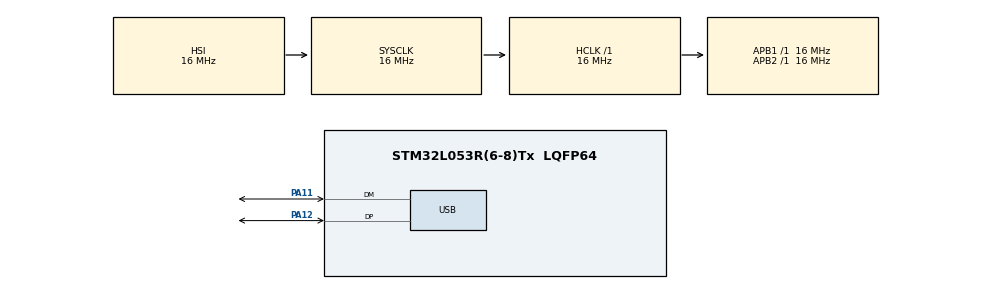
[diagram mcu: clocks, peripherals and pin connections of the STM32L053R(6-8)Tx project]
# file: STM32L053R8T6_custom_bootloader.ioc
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Mcu.Family=STM32L0
Mcu.Name=STM32L053R(6-8)Tx
Mcu.Package=LQFP64
NVIC.USB_IRQn=true\:0\:0\:false\:false\:true\:false\:true
PA11.Mode=Device
PA11.Signal=USB_DM
PA12.Mode=Device
PA12.Signal=USB_DP
PH0-OSC_IN.Mode=HSE-External-Clock-Source
PH0-OSC_IN.Signal=RCC_OSC_IN
ProjectManager.HeapSize=0x200
ProjectManager.StackSize=0x400
ProjectManager.TargetToolchain=STM32CubeIDE
RCC.AHBFreq_Value=16000000
RCC.APB1Freq_Value=16000000
RCC.APB1TimFreq_Value=16000000
RCC.APB2Freq_Value=16000000
RCC.APB2TimFreq_Value=16000000
RCC.HCLKFreq_Value=16000000
RCC.HSE_VALUE=8000000
RCC.HSI16_VALUE=16000000
RCC.HSI48MClockSelection=RCC_USBCLKSOURCE_HSI48
RCC.HSI48_VALUE=48000000
RCC.HSI_VALUE=16000000
RCC.LSE_VALUE=32768
RCC.MSI_VALUE=2097000
RCC.SYSCLKFreq_VALUE=16000000
RCC.SYSCLKSource=RCC_SYSCLKSOURCE_HSI
RCC.VCOOutputFreq_Value=48000000
USB_DEVICE.CLASS_NAME_FS=DFU
USB_DEVICE.USBD_DFU_APP_DEFAULT_ADD=0x08004000
USB_DEVICE.USBD_DFU_MEDIA=@Internal Flash   /0x08000000/128*128Ba,384*128Bg
USB_DEVICE.VirtualMode=Dfu
USB_DEVICE.VirtualModeFS=Dfu_FS
VP_USB_DEVICE_VS_USB_DEVICE_DFU_FS.Mode=DFU_FS
board=custom

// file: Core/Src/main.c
/* USER CODE BEGIN Header */
/**
  ******************************************************************************
  * @file           : main.c
  * @brief          : Main program body
  ******************************************************************************
  * @attention
  *
  * <h2><center>&copy; Copyright (c) 2021 STMicroelectronics.
  * All rights reserved.</center></h2>
  *
  * This software component is licensed by ST under Ultimate Liberty license
  * SLA0044, the "License"; You may not use this file except in compliance with
  * the License. You may obtain a copy of the License at:
  *                             www.st.com/SLA0044
  *
  ******************************************************************************
  */
/* USER CODE END Header */
#include "main.h"
#include "gpio.h"

/* USER CODE BEGIN Includes */
#include "usb_device.h"

#define EEPROM_ADDRESS 0x08080000
#define EEPROM_DFU_FLAG 100
/* USER CODE END Includes */

/* USER CODE BEGIN PV */
#if 0
HAL_StatusTypeDef eeprom_read_bit_32(uint16_t addr_idx, uint32_t *value);
HAL_StatusTypeDef eeprom_read_bit_32_type(uint32_t *value, uint16_t idx);
#endif
/* USER CODE END PV */

void SystemClock_Config(void);

int main(void)
{
  /* USER CODE BEGIN 1 */
  typedef void (*pFunction)(void);
  uint32_t JumpAddress;
  void (*Jump_To_Application)();
  /* USER CODE END 1 */

  /* MCU Configuration--------------------------------------------------------*/

  /* Reset of all peripherals, Initializes the Flash interface and the Systick. */
  HAL_Init();

  /* Configure the system clock */
  SystemClock_Config();

  /* Initialize all configured peripherals */
  MX_GPIO_Init();
  /* USER CODE BEGIN 2 */
  uint32_t main_get_dfu = *(uint32_t*)(EEPROM_ADDRESS + EEPROM_DFU_FLAG * 4);

#if 0
  eeprom_read_bit_32_type(&main_get_dfu,EEPROM_DFU_FLAG); // get dfu flag from eeprom idx 100
#endif

  if(main_get_dfu != 0x98765432)
  {
    JumpAddress = *(__IO uint32_t*) (USBD_DFU_APP_DEFAULT_ADD + 4);
    Jump_To_Application = (pFunction) JumpAddress;
    __set_MSP(*(__IO uint32_t*) USBD_DFU_APP_DEFAULT_ADD);
    Jump_To_Application();
  }

	MX_USB_DEVICE_Init();
  /* USER CODE END 2 */

  /* Infinite loop */
  while (1)
  {

  }
}

void SystemClock_Config(void)
{
  RCC_OscInitTypeDef RCC_OscInitStruct = {0};
  RCC_ClkInitTypeDef RCC_ClkInitStruct = {0};
  RCC_PeriphCLKInitTypeDef PeriphClkInit = {0};

  /** Configure the main internal regulator output voltage
  */
  __HAL_PWR_VOLTAGESCALING_CONFIG(PWR_REGULATOR_VOLTAGE_SCALE1);
  /** Initializes the RCC Oscillators according to the specified parameters
  * in the RCC_OscInitTypeDef structure.
  */
  RCC_OscInitStruct.OscillatorType = RCC_OSCILLATORTYPE_HSI|RCC_OSCILLATORTYPE_HSI48;
  RCC_OscInitStruct.HSIState = RCC_HSI_ON;
  RCC_OscInitStruct.HSICalibrationValue = RCC_HSICALIBRATION_DEFAULT;
  RCC_OscInitStruct.HSI48State = RCC_HSI48_ON;
  RCC_OscInitStruct.PLL.PLLState = RCC_PLL_NONE;
  if (HAL_RCC_OscConfig(&RCC_OscInitStruct) != HAL_OK)
  {
    Error_Handler();
  }
  /** Initializes the CPU, AHB and APB buses clocks
  */
  RCC_ClkInitStruct.ClockType = RCC_CLOCKTYPE_HCLK|RCC_CLOCKTYPE_SYSCLK
                              |RCC_CLOCKTYPE_PCLK1|RCC_CLOCKTYPE_PCLK2;
  RCC_ClkInitStruct.SYSCLKSource = RCC_SYSCLKSOURCE_HSI;
  RCC_ClkInitStruct.AHBCLKDivider = RCC_SYSCLK_DIV1;
  RCC_ClkInitStruct.APB1CLKDivider = RCC_HCLK_DIV1;
  RCC_ClkInitStruct.APB2CLKDivider = RCC_HCLK_DIV1;

  if (HAL_RCC_ClockConfig(&RCC_ClkInitStruct, FLASH_LATENCY_0) != HAL_OK)
  {
    Error_Handler();
  }
  PeriphClkInit.PeriphClockSelection = RCC_PERIPHCLK_USB;
  PeriphClkInit.UsbClockSelection = RCC_USBCLKSOURCE_HSI48;
  if (HAL_RCCEx_PeriphCLKConfig(&PeriphClkInit) != HAL_OK)
  {
    Error_Handler();
  }
}

/* USER CODE BEGIN 4 */
#if 0
HAL_StatusTypeDef eeprom_read_bit_32(uint16_t addr_idx, uint32_t *value)
{
  *value = *(uint32_t*)(EEPROM_ADDRESS + addr_idx * 4);

  return HAL_OK;
}

HAL_StatusTypeDef eeprom_read_bit_32_type(uint32_t *value, uint16_t idx)
{
  if (eeprom_read_bit_32(idx, value) != HAL_OK)
  {
    return HAL_ERROR;
  }

  return HAL_OK;
}
#endif
/* USER CODE END 4 */

void Error_Handler(void)
{
  __disable_irq();
  while (1)
  {
  }
}

/************************ (C) COPYRIGHT STMicroelectronics *****END OF FILE****/
